# GD32E501 register map
File version: 1.0
CPU: CM33 r0p4, little endian, MPU, FPU, 4 interrupt priority bits
Registers are 32-bit, read-write, reset 0x0 unless marked. A register's access mark holds for its fields unless they carry their own. Offsets are from the block's base; [hi:lo] are bit positions.

## TIMER15 — General-purpose-timers
Base 0x40014400
Same registers: TIMER16 0x40014800
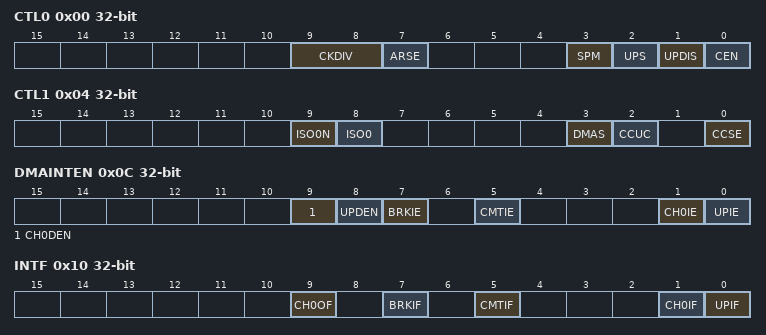
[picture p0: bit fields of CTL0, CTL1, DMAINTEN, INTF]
0x00 CTL0 — control register 0
  [9:8] CKDIV — Clock division
  [7] ARSE — Auto-reload preload enable
  [3] SPM — One-pulse mode
  [2] UPS — Update request source
  [1] UPDIS — Update disable
  [0] CEN — Counter enable
0x04 CTL1 — control register 1
  [9] ISO0N — Output Idle state 0
  [8] ISO0 — Output Idle state 0
  [3] DMAS — Capture/compare DMA selection
  [2] CCUC — Capture/compare control update selection
  [0] CCSE — Capture/compare preloaded control
0x0C DMAINTEN — DMA/Interrupt enable register
  [9] CH0DEN — Capture/Compare 0 DMA request enable
  [8] UPDEN — Update DMA request enable
  [7] BRKIE — Break interrupt enable
  [5] CMTIE — COM interrupt enable
  [1] CH0IE — Capture/Compare 0 interrupt enable
  [0] UPIE — Update interrupt enable
0x10 INTF — interrupt flag register
  [9] CH0OF — Capture/Compare 0 overcapture flag
  [7] BRKIF — Break interrupt flag
  [5] CMTIF — COM interrupt flag
  [1] CH0IF — Capture/compare 0 interrupt flag
  [0] UPIF — Update interrupt flag
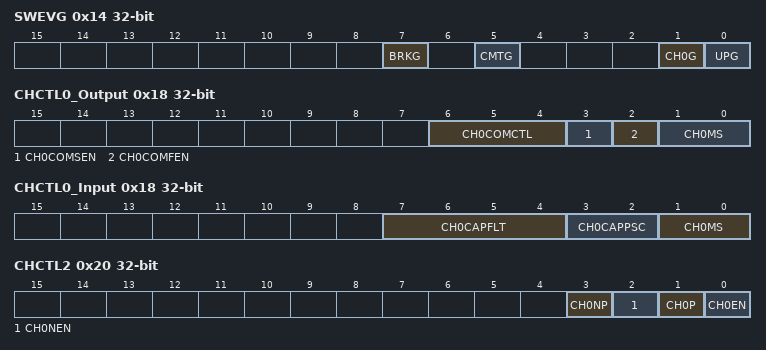
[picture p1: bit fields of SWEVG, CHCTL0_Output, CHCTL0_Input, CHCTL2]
0x14 SWEVG wo — event generation register
  [7] BRKG — Break generation
  [5] CMTG — Capture/Compare control update generation
  [1] CH0G — Capture/compare 0 generation
  [0] UPG — Update generation
0x18 CHCTL0_Output — capture/compare mode register (output mode)
  [6:4] CH0COMCTL — Output Compare 0 mode
  [3] CH0COMSEN — Output Compare 0 preload enable
  [2] CH0COMFEN — Output Compare 0 fast enable
  [1:0] CH0MS — Capture/Compare 0 selection
0x18 CHCTL0_Input (alternate view of CHCTL0_Output) — capture/compare mode register 0 (input mode)
  [7:4] CH0CAPFLT — Input capture 0 filter
  [3:2] CH0CAPPSC — Input capture 0 prescaler
  [1:0] CH0MS — Capture/Compare 0 selection
0x20 CHCTL2 — capture/compare enable register
  [3] CH0NP — Capture/Compare 0 output Polarity
  [2] CH0NEN — Capture/Compare 0 complementary output enable
  [1] CH0P — Capture/Compare 0 output Polarity
  [0] CH0EN — Capture/Compare 0 output enable
0x24 CNT — counter
  [15:0] CNT — counter value
0x28 PSC — prescaler
  [15:0] PSC — Prescaler value
0x2C CAR — auto-reload register
  [15:0] CARL — Auto-reload value
0x30 CREP — repetition counter register
  [7:0] CREP — Repetition counter value
0x34 CH0CV — capture/compare register 0
  [15:0] CH0VAL — Capture/Compare 0 value
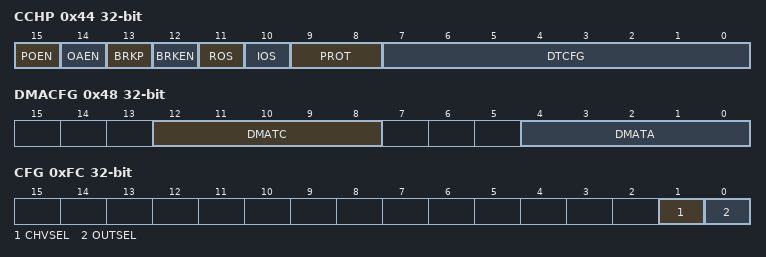
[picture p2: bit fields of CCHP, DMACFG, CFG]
0x44 CCHP — break and dead-time register
  [15] POEN — Main output enable
  [14] OAEN — Automatic output enable
  [13] BRKP — Break polarity
  [12] BRKEN — Break enable
  [11] ROS — Off-state selection for Run mode
  [10] IOS — Off-state selection for Idle mode
  [9:8] PROT — complementary register protect control
  [7:0] DTCFG — Dead-time generator setup
0x48 DMACFG — DMA configuration register
  [12:8] DMATC — DMA transfer count
  [4:0] DMATA — DMA transfer access start address
0x4C DMATB — DMA transfer buffer register
  [15:0] DMATB — DMA register for burst accesses
0xFC CFG — configuration register
  [1] CHVSEL — Write CHxVAL register selection
  [0] OUTSEL — The output value selection

## USART1 — Universal synchronous asynchronous receiver transmitter
Base 0x40004400
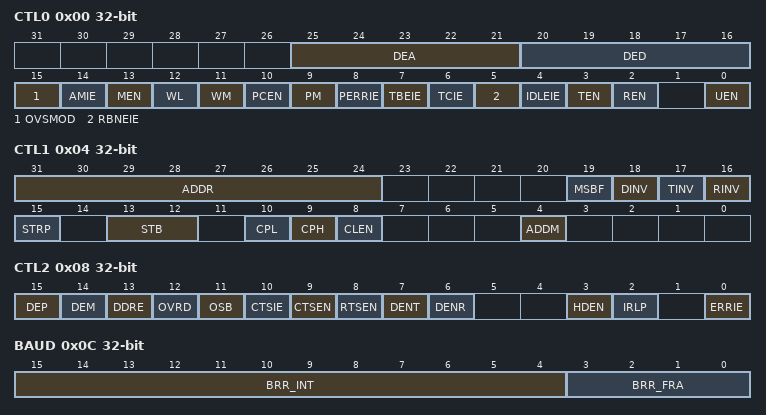
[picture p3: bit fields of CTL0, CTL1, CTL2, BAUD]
0x00 CTL0 — Control register 0
  [25:21] DEA — Driver Enable assertion time
  [20:16] DED — Driver Enable deassertion time
  [15] OVSMOD — Oversampling mode
  [14] AMIE — Character match interrupt enable
  [13] MEN — Mute mode enable
  [12] WL — Word length
  [11] WM — Receiver wakeup method
  [10] PCEN — Parity control enable
  [9] PM — Parity selection
  [8] PERRIE — PE interrupt enable
  [7] TBEIE — interrupt enable
  [6] TCIE — Transmission complete interrupt enable
  [5] RBNEIE — RXNE interrupt enable
  [4] IDLEIE — IDLE interrupt enable
  [3] TEN — Transmitter enable
  [2] REN — Receiver enable
  [0] UEN — USART enable
0x04 CTL1 — Control register 1
  [31:24] ADDR — Address of the USART terminal
  [19] MSBF — Most significant bit first
  [18] DINV — Data bit level inversion
  [17] TINV — TX pin active level inversion
  [16] RINV — RX pin active level inversion
  [15] STRP — Swap TX/RX pins
  [13:12] STB — STOP bits
  [10] CPL — Clock polarity
  [9] CPH — Clock phase
  [8] CLEN — Last bit clock pulse
  [4] ADDM — 7-bit Address Detection/4-bit Address Detection
0x08 CTL2 — Control register 2
  [15] DEP — Driver enable polarity selection
  [14] DEM — Driver enable mode
  [13] DDRE — DMA Disable on Reception Error
  [12] OVRD — Overrun Disable
  [11] OSB — One sample bit method enable
  [10] CTSIE — CTS interrupt enable
  [9] CTSEN — CTS enable
  [8] RTSEN — RTS enable
  [7] DENT — DMA enable transmitter
  [6] DENR — DMA enable receiver
  [3] HDEN — Half-duplex selection
  [2] IRLP — IrDA low-power
  [0] ERRIE — Error interrupt enable
0x0C BAUD — Baud rate register
  [15:4] BRR_INT — integer of baud-rate divider
  [3:0] BRR_FRA — integer of baud-rate divider
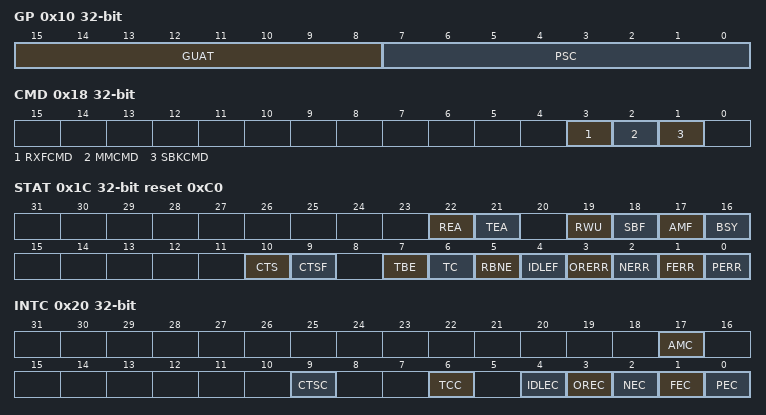
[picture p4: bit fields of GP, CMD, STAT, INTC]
0x10 GP — Guard time and prescaler register
  [15:8] GUAT — Guard time value
  [7:0] PSC — Prescaler value
0x18 CMD wo — Command register
  [3] RXFCMD — Receive data flush request
  [2] MMCMD — Mute mode request
  [1] SBKCMD — Send break request
0x1C STAT ro reset 0xC0 — Interrupt & status register
  [22] REA — Receive enable acknowledge flag
  [21] TEA — Transmit enable acknowledge flag
  [19] RWU — Receiver wakeup from Mute mode
  [18] SBF — Send break flag
  [17] AMF — character match flag
  [16] BSY — Busy flag
  [10] CTS — CTS flag
  [9] CTSF — CTS interrupt flag
  [7] TBE — Transmit data register empty
  [6] TC — Transmission complete
  [5] RBNE — Read data register not empty
  [4] IDLEF — Idle line detected
  [3] ORERR — Overrun error
  [2] NERR — Noise detected flag
  [1] FERR — Framing error
  [0] PERR — Parity error
0x20 INTC wo — Interrupt flag clear register
  [17] AMC — Character match clear flag
  [9] CTSC — CTS clear flag
  [6] TCC — Transmission complete clear flag
  [4] IDLEC — Idle line detected clear flag
  [3] OREC — Overrun error clear flag
  [2] NEC — Noise detected clear flag
  [1] FEC — Frame error clear flag
  [0] PEC — Parity error clear flag
0x24 RDATA ro — Receive data register
  [8:0] RDATA — Receive data value
0x28 TDATA — Transmit data register
  [8:0] TDATA — Transmit data value
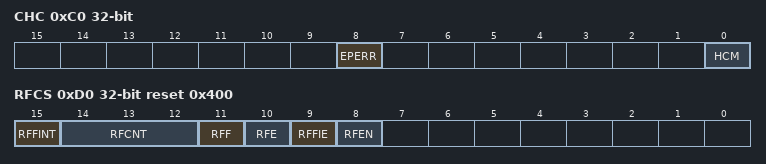
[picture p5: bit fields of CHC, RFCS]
0xC0 CHC — coherence control register
  [8] EPERR — Early parity error flag
  [0] HCM — Hardware flow control coherence mode
0xD0 RFCS access per field reset 0x400 — USART receive FIFO control and status register
  [15] RFFINT rw — Receive FIFO full interrupt flag
  [14:12] RFCNT ro — Receive FIFO count number
  [11] RFF ro — Receive FIFO full flag
  [10] RFE ro — Receive FIFO empty flag
  [9] RFFIE rw — Receive FIFO full interrupt enable
  [8] RFEN rw — Receive FIFO enable

## WWDGT — Window watchdog timer
Base 0x40002C00
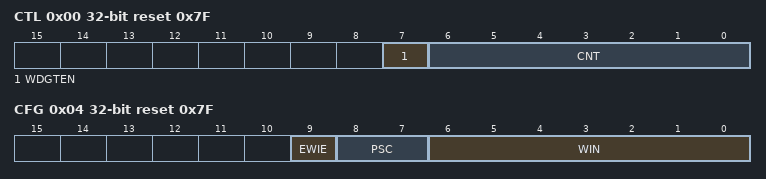
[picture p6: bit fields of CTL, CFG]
0x00 CTL reset 0x7F — Control register
  [7] WDGTEN — Activation bit
  [6:0] CNT — 7-bit counter
0x04 CFG reset 0x7F — Configuration register
  [9] EWIE — Early wakeup interrupt
  [8:7] PSC — Prescaler
  [6:0] WIN — 7-bit window value
0x08 STAT — Status register
  [0] EWIF — Early wakeup interrupt flag
